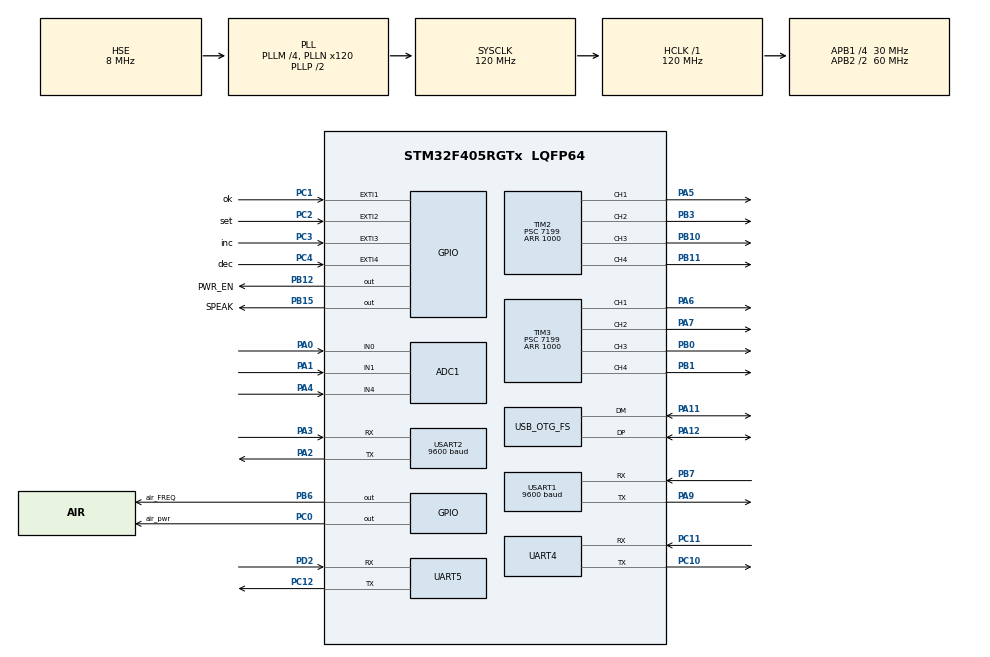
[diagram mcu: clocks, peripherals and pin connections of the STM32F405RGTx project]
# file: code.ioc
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ADC1.Channel-0\#ChannelRegularConversion=ADC_CHANNEL_0
ADC1.Channel-1\#ChannelRegularConversion=ADC_CHANNEL_1
ADC1.Channel-2\#ChannelRegularConversion=ADC_CHANNEL_4
ADC1.Channel-3\#ChannelRegularConversion=ADC_CHANNEL_VREFINT
ADC1.ContinuousConvMode=ENABLE
ADC1.DMAContinuousRequests=ENABLE
ADC1.NbrOfConversion=4
ADC1.NbrOfConversionFlag=1
ADC1.Rank-0\#ChannelRegularConversion=1
ADC1.Rank-1\#ChannelRegularConversion=2
ADC1.Rank-2\#ChannelRegularConversion=3
ADC1.Rank-3\#ChannelRegularConversion=4
ADC1.SamplingTime-0\#ChannelRegularConversion=ADC_SAMPLETIME_56CYCLES
ADC1.SamplingTime-1\#ChannelRegularConversion=ADC_SAMPLETIME_56CYCLES
ADC1.SamplingTime-2\#ChannelRegularConversion=ADC_SAMPLETIME_56CYCLES
ADC1.SamplingTime-3\#ChannelRegularConversion=ADC_SAMPLETIME_56CYCLES
ADC1.master=1
Dma.ADC1.2.Direction=DMA_PERIPH_TO_MEMORY
Dma.ADC1.2.FIFOMode=DMA_FIFOMODE_DISABLE
Dma.ADC1.2.Instance=DMA2_Stream0
Dma.ADC1.2.MemDataAlignment=DMA_MDATAALIGN_WORD
Dma.ADC1.2.MemInc=DMA_MINC_ENABLE
Dma.ADC1.2.Mode=DMA_CIRCULAR
Dma.ADC1.2.PeriphDataAlignment=DMA_PDATAALIGN_WORD
Dma.ADC1.2.PeriphInc=DMA_PINC_DISABLE
Dma.ADC1.2.Priority=DMA_PRIORITY_LOW
Dma.Request0=UART5_RX
Dma.Request1=USART2_RX
Dma.Request2=ADC1
Dma.Request3=UART4_RX
Dma.Request4=USART1_RX
Dma.UART4_RX.3.Direction=DMA_PERIPH_TO_MEMORY
Dma.UART4_RX.3.FIFOMode=DMA_FIFOMODE_DISABLE
Dma.UART4_RX.3.Instance=DMA1_Stream2
Dma.UART4_RX.3.MemDataAlignment=DMA_MDATAALIGN_BYTE
Dma.UART4_RX.3.MemInc=DMA_MINC_ENABLE
Dma.UART4_RX.3.Mode=DMA_NORMAL
Dma.UART4_RX.3.PeriphDataAlignment=DMA_PDATAALIGN_BYTE
Dma.UART4_RX.3.PeriphInc=DMA_PINC_DISABLE
Dma.UART4_RX.3.Priority=DMA_PRIORITY_LOW
Dma.UART5_RX.0.Direction=DMA_PERIPH_TO_MEMORY
Dma.UART5_RX.0.FIFOMode=DMA_FIFOMODE_DISABLE
Dma.UART5_RX.0.Instance=DMA1_Stream0
Dma.UART5_RX.0.MemDataAlignment=DMA_MDATAALIGN_BYTE
Dma.UART5_RX.0.MemInc=DMA_MINC_ENABLE
Dma.UART5_RX.0.Mode=DMA_NORMAL
Dma.UART5_RX.0.PeriphDataAlignment=DMA_PDATAALIGN_BYTE
Dma.UART5_RX.0.PeriphInc=DMA_PINC_DISABLE
Dma.UART5_RX.0.Priority=DMA_PRIORITY_LOW
Dma.USART1_RX.4.Direction=DMA_PERIPH_TO_MEMORY
Dma.USART1_RX.4.FIFOMode=DMA_FIFOMODE_DISABLE
Dma.USART1_RX.4.Instance=DMA2_Stream2
Dma.USART1_RX.4.MemDataAlignment=DMA_MDATAALIGN_BYTE
Dma.USART1_RX.4.MemInc=DMA_MINC_ENABLE
Dma.USART1_RX.4.Mode=DMA_NORMAL
Dma.USART1_RX.4.PeriphDataAlignment=DMA_PDATAALIGN_BYTE
Dma.USART1_RX.4.PeriphInc=DMA_PINC_DISABLE
Dma.USART1_RX.4.Priority=DMA_PRIORITY_LOW
Dma.USART2_RX.1.Direction=DMA_PERIPH_TO_MEMORY
Dma.USART2_RX.1.FIFOMode=DMA_FIFOMODE_DISABLE
Dma.USART2_RX.1.Instance=DMA1_Stream5
Dma.USART2_RX.1.MemDataAlignment=DMA_MDATAALIGN_BYTE
Dma.USART2_RX.1.MemInc=DMA_MINC_ENABLE
Dma.USART2_RX.1.Mode=DMA_NORMAL
Dma.USART2_RX.1.PeriphDataAlignment=DMA_PDATAALIGN_BYTE
Dma.USART2_RX.1.PeriphInc=DMA_PINC_DISABLE
Dma.USART2_RX.1.Priority=DMA_PRIORITY_LOW
FATFS._CODE_PAGE=936
FATFS._MAX_SS=4096
FATFS._USE_LFN=2
FATFS._VOLUMES=3
Mcu.Family=STM32F4
Mcu.Name=STM32F405RGTx
Mcu.Package=LQFP64
NVIC.ADC_IRQn=true\:0\:0\:false\:false\:true\:true\:true\:true
NVIC.DMA1_Stream0_IRQn=true\:0\:0\:false\:false\:true\:false\:true\:true
NVIC.DMA1_Stream2_IRQn=true\:0\:0\:false\:false\:true\:false\:true\:true
NVIC.DMA1_Stream5_IRQn=true\:0\:0\:false\:false\:true\:false\:true\:true
NVIC.DMA2_Stream0_IRQn=true\:0\:0\:false\:false\:true\:false\:true\:true
NVIC.DMA2_Stream2_IRQn=true\:0\:0\:false\:false\:true\:false\:true\:true
NVIC.EXTI1_IRQn=true\:0\:0\:false\:false\:true\:true\:true\:true
NVIC.EXTI2_IRQn=true\:0\:0\:false\:false\:true\:true\:true\:true
NVIC.EXTI3_IRQn=true\:0\:0\:false\:false\:true\:true\:true\:true
NVIC.EXTI4_IRQn=true\:0\:0\:false\:false\:true\:true\:true\:true
NVIC.OTG_FS_IRQn=true\:0\:0\:true\:false\:true\:false\:true\:true
NVIC.PVD_IRQn=true\:0\:0\:false\:false\:true\:true\:true\:true
NVIC.PriorityGroup=NVIC_PRIORITYGROUP_4
NVIC.TIM4_IRQn=true\:0\:0\:false\:false\:true\:true\:true\:true
NVIC.UART4_IRQn=true\:0\:0\:false\:false\:true\:true\:true\:true
NVIC.UART5_IRQn=true\:0\:0\:false\:false\:true\:true\:true\:true
NVIC.USART1_IRQn=true\:0\:0\:false\:false\:true\:true\:true\:true
NVIC.USART2_IRQn=true\:0\:0\:false\:false\:true\:true\:true\:true
PA0-WKUP.Signal=ADCx_IN0
PA1.Signal=ADCx_IN1
PA11.Mode=Host_Only
PA11.Signal=USB_OTG_FS_DM
PA12.Mode=Host_Only
PA12.Signal=USB_OTG_FS_DP
PA13.Mode=Serial_Wire
PA13.Signal=SYS_JTMS-SWDIO
PA14.Mode=Serial_Wire
PA14.Signal=SYS_JTCK-SWCLK
PA2.Mode=Asynchronous
PA2.Signal=USART2_TX
PA3.Mode=Asynchronous
PA3.Signal=USART2_RX
PA4.Signal=ADCx_IN4
PA5.Signal=S_TIM2_CH1_ETR
PA6.Signal=S_TIM3_CH1
PA7.Signal=S_TIM3_CH2
PA9.Mode=Asynchronous
PA9.Signal=USART1_TX
PB0.Signal=S_TIM3_CH3
PB1.Signal=S_TIM3_CH4
PB10.Signal=S_TIM2_CH3
PB11.Signal=S_TIM2_CH4
PB12.GPIO_Label=PWR_EN
PB12.Signal=GPIO_Output
PB15.GPIO_Label=SPEAK
PB15.Signal=GPIO_Output
PB3.Signal=S_TIM2_CH2
PB6.GPIO_Label=air_FREQ
PB6.Signal=GPIO_Output
PB7.Mode=Asynchronous
PB7.Signal=USART1_RX
PC0.GPIO_Label=air_pwr
PC0.Signal=GPIO_Output
PC1.GPIO_Label=ok
PC1.GPIO_ModeDefaultEXTI=GPIO_MODE_IT_FALLING
PC1.GPIO_PuPd=GPIO_PULLUP
PC1.Signal=GPXTI1
PC10.Mode=Asynchronous
PC10.Signal=UART4_TX
PC11.Mode=Asynchronous
PC11.Signal=UART4_RX
PC12.Mode=Asynchronous
PC12.Signal=UART5_TX
PC2.GPIO_Label=set
PC2.GPIO_ModeDefaultEXTI=GPIO_MODE_IT_FALLING
PC2.GPIO_PuPd=GPIO_PULLUP
PC2.Signal=GPXTI2
PC3.GPIO_Label=inc
PC3.GPIO_ModeDefaultEXTI=GPIO_MODE_IT_FALLING
PC3.GPIO_PuPd=GPIO_PULLUP
PC3.Signal=GPXTI3
PC4.GPIO_Label=dec
PC4.GPIO_ModeDefaultEXTI=GPIO_MODE_IT_FALLING
PC4.GPIO_PuPd=GPIO_PULLUP
PC4.Signal=GPXTI4
PD2.Mode=Asynchronous
PD2.Signal=UART5_RX
PH0-OSC_IN.Mode=HSE-External-Oscillator
PH0-OSC_IN.Signal=RCC_OSC_IN
PH1-OSC_OUT.Mode=HSE-External-Oscillator
PH1-OSC_OUT.Signal=RCC_OSC_OUT
ProjectManager.HeapSize=0x2000
ProjectManager.StackSize=0x2000
ProjectManager.TargetToolchain=MDK-ARM V5.32
RCC.48MHZClocksFreq_Value=48000000
RCC.AHBFreq_Value=120000000
RCC.APB1CLKDivider=RCC_HCLK_DIV4
RCC.APB1Freq_Value=30000000
RCC.APB1TimFreq_Value=60000000
RCC.APB2CLKDivider=RCC_HCLK_DIV2
RCC.APB2Freq_Value=60000000
RCC.APB2TimFreq_Value=120000000
RCC.CortexFreq_Value=120000000
RCC.HCLKFreq_Value=120000000
RCC.HSE_VALUE=8000000
RCC.HSI_VALUE=16000000
RCC.LSE_VALUE=32768
RCC.PLLM=4
RCC.PLLN=120
RCC.PLLQ=5
RCC.SYSCLKFreq_VALUE=120000000
RCC.SYSCLKSource=RCC_SYSCLKSOURCE_PLLCLK
RCC.VCOOutputFreq_Value=240000000
RTC.Format=RTC_FORMAT_BIN
RTC.Hours=14
RTC.Minutes=55
RTC.SynchPrediv=249
RTC.WakeUpClock=RTC_WAKEUPCLOCK_CK_SPRE_16BITS
RTC.WakeUpCounter=3600
RTC.Year=15
SH.ADCx_IN0.0=ADC1_IN0,IN0
SH.ADCx_IN1.0=ADC1_IN1,IN1
SH.ADCx_IN4.0=ADC1_IN4,IN4
SH.S_TIM2_CH1_ETR.0=TIM2_CH1,PWM Generation1 CH1
SH.S_TIM2_CH2.0=TIM2_CH2,PWM Generation2 CH2
SH.S_TIM2_CH3.0=TIM2_CH3,PWM Generation3 CH3
SH.S_TIM2_CH4.0=TIM2_CH4,PWM Generation4 CH4
SH.S_TIM3_CH1.0=TIM3_CH1,PWM Generation1 CH1
SH.S_TIM3_CH2.0=TIM3_CH2,PWM Generation2 CH2
SH.S_TIM3_CH3.0=TIM3_CH3,PWM Generation3 CH3
SH.S_TIM3_CH4.0=TIM3_CH4,PWM Generation4 CH4
TIM2.AutoReloadPreload=TIM_AUTORELOAD_PRELOAD_ENABLE
TIM2.Channel-PWM\ Generation1\ CH1=TIM_CHANNEL_1
TIM2.Channel-PWM\ Generation2\ CH2=TIM_CHANNEL_2
TIM2.Channel-PWM\ Generation3\ CH3=TIM_CHANNEL_3
TIM2.Channel-PWM\ Generation4\ CH4=TIM_CHANNEL_4
TIM2.Period=1000
TIM2.Prescaler=7199
TIM3.Channel-PWM\ Generation1\ CH1=TIM_CHANNEL_1
TIM3.Channel-PWM\ Generation2\ CH2=TIM_CHANNEL_2
TIM3.Channel-PWM\ Generation3\ CH3=TIM_CHANNEL_3
TIM3.Channel-PWM\ Generation4\ CH4=TIM_CHANNEL_4
TIM3.Period=1000
TIM3.Prescaler=7199
TIM3.Pulse-PWM\ Generation1\ CH1=5
TIM4.AutoReloadPreload=TIM_AUTORELOAD_PRELOAD_ENABLE
TIM4.Period=999
TIM4.Prescaler=71
UART4.VirtualMode=Asynchronous
UART5.VirtualMode=Asynchronous
USART1.BaudRate=9600
USART1.VirtualMode=VM_ASYNC
USART2.BaudRate=9600
USART2.VirtualMode=VM_ASYNC
USB_HOST.USBH_DEBUG_LEVEL-MSC_FS=2
USB_HOST.USBH_HandleTypeDef-MSC_FS=hUsbHostFS
USB_HOST.VirtualModeFS=Msc
USB_OTG_FS.VirtualMode=Host_Only
USB_OTG_FS.phy_itface=HCD_PHY_EMBEDDED
VP_ADC1_Vref_Input.Mode=IN-Vrefint
VP_FATFS_VS_USB.Mode=USB
VP_RTC_VS_RTC_Activate.Mode=RTC_Enabled
VP_RTC_VS_RTC_WakeUp_intern.Mode=WakeUp
VP_TIM4_VS_ClockSourceINT.Mode=Internal
VP_USB_HOST_VS_USB_HOST_MSC_FS.Mode=MSC_FS
board=custom

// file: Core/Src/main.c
/* USER CODE BEGIN Header */
/**
  ******************************************************************************
  * @file           : main.c
  * @brief          : Main program body
  ******************************************************************************
  * @attention
  *
  * Copyright (c) 2024 STMicroelectronics.
  * All rights reserved.
  *
  * This software is licensed under terms that can be found in the LICENSE file
  * in the root directory of this software component.
  * If no LICENSE file comes with this software, it is provided AS-IS.
  *
  ******************************************************************************
  */
/* USER CODE END Header */
#include "main.h"
#include "fatfs.h"
#include "usb_host.h"

/* USER CODE BEGIN Includes */
#include "air.h"

/* USER CODE END Includes */

ADC_HandleTypeDef hadc1;
DMA_HandleTypeDef hdma_adc1;

RTC_HandleTypeDef hrtc;

TIM_HandleTypeDef htim2;
TIM_HandleTypeDef htim3;
TIM_HandleTypeDef htim4;

UART_HandleTypeDef huart4;
UART_HandleTypeDef huart5;
UART_HandleTypeDef huart1;
UART_HandleTypeDef huart2;
DMA_HandleTypeDef hdma_uart4_rx;
DMA_HandleTypeDef hdma_uart5_rx;
DMA_HandleTypeDef hdma_usart1_rx;
DMA_HandleTypeDef hdma_usart2_rx;

/* USER CODE BEGIN PV */
USBH_HandleTypeDef hUSBHost;    /* USB Host处理结构体 */
/* USER CODE END PV */

void SystemClock_Config(void);
static void MX_GPIO_Init(void);
static void MX_DMA_Init(void);
static void MX_ADC1_Init(void);
static void MX_TIM2_Init(void);
static void MX_TIM3_Init(void);
static void MX_UART4_Init(void);
static void MX_USART1_UART_Init(void);
static void MX_USART2_UART_Init(void);
static void MX_UART5_Init(void);
static void MX_TIM4_Init(void);
static void MX_RTC_Init(void);
void MX_USB_HOST_Process(void);

/* USER CODE BEGIN PFP */
FATFS *fs[FF_VOLUMES];
/* USER CODE END PFP */

/* USER CODE BEGIN 0 */
//static void USBH_UserProcess(USBH_HandleTypeDef *phost, uint8_t id)
//{
//    uint32_t total, free;
//    uint8_t res = 0;
//    printf("id:%d\r\n", id);

//    switch (id)
//    {
//        case HOST_USER_SELECT_CONFIGURATION:
//            break;

//        case HOST_USER_DISCONNECTION:
//            f_mount(0, "2:", 1);        /* 卸载U盘 */
//           // text_show_string(30, 120, 200, 16, "设备连接中...", 16, 0, RED);
//            //lcd_fill(30, 160, 239, 220, WHITE);
//            break;

//        case HOST_USER_CLASS_ACTIVE:
//            //text_show_string(30, 120, 200, 16, "设备连接成功!", 16, 0, RED);
//            f_mount(fs[2], "2:", 1);    /* 重新挂载U盘 */
//            res = exfuns_get_free("2:", &total, &free);

//            if (res == 0)
//            {
////                lcd_show_string(30, 160, 200, 16, 16, "FATFS OK!", BLUE);
////                lcd_show_string(30, 180, 200, 16, 16, "U Disk Total Size:     MB", BLUE);
////                lcd_show_string(30, 200, 200, 16, 16, "U Disk  Free Size:     MB", BLUE);
////                lcd_show_num(174, 180, total >> 10, 5, 16, BLUE);   /* 显示U盘总容量 MB */
////                lcd_show_num(174, 200, free >> 10, 5, 16, BLUE);
//            }
//            else
//            {
//                printf("U盘存储空间获取失败\r\n");
//            }

//            break;

//        case HOST_USER_CONNECTION:
//            break;

//        default:
//            break;
//    }
//}
/* USER CODE END 0 */

int main(void)
{

  /* MCU Configuration--------------------------------------------------------*/

  /* Reset of all peripherals, Initializes the Flash interface and the Systick. */
  HAL_Init();

  /* Configure the system clock */
  SystemClock_Config();

  /* Initialize all configured peripherals */
  MX_GPIO_Init();
  MX_DMA_Init();
  MX_ADC1_Init();
  MX_TIM2_Init();
  MX_TIM3_Init();
  MX_UART4_Init();
  MX_USART1_UART_Init();
  MX_USART2_UART_Init();
  MX_UART5_Init();
  MX_TIM4_Init();
  MX_FATFS_Init();
  MX_USB_HOST_Init();
  MX_RTC_Init();
  /* USER CODE BEGIN 2 */
  //  USBH_Init(&hUSBHost, USBH_UserProcess, 0);
    USBH_RegisterClass(&hUSBHost, USBH_MSC_CLASS);
    USBH_Start(&hUSBHost);
	app_init();
  /* USER CODE END 2 */

  /* Infinite loop */
  while (1)
  {
    MX_USB_HOST_Process();

    /* USER CODE BEGIN 3 */
		app();
		HAL_GPIO_WritePin(PWR_EN_GPIO_Port, PWR_EN_Pin, GPIO_PIN_SET);
  }
  /* USER CODE END 3 */
}

void SystemClock_Config(void)
{
  RCC_OscInitTypeDef RCC_OscInitStruct = {0};
  RCC_ClkInitTypeDef RCC_ClkInitStruct = {0};

  /** Configure the main internal regulator output voltage
  */
  __HAL_RCC_PWR_CLK_ENABLE();
  __HAL_PWR_VOLTAGESCALING_CONFIG(PWR_REGULATOR_VOLTAGE_SCALE1);

  /** Initializes the RCC Oscillators according to the specified parameters
  * in the RCC_OscInitTypeDef structure.
  */
  RCC_OscInitStruct.OscillatorType = RCC_OSCILLATORTYPE_LSI|RCC_OSCILLATORTYPE_HSE;
  RCC_OscInitStruct.HSEState = RCC_HSE_ON;
  RCC_OscInitStruct.LSIState = RCC_LSI_ON;
  RCC_OscInitStruct.PLL.PLLState = RCC_PLL_ON;
  RCC_OscInitStruct.PLL.PLLSource = RCC_PLLSOURCE_HSE;
  RCC_OscInitStruct.PLL.PLLM = 4;
  RCC_OscInitStruct.PLL.PLLN = 120;
  RCC_OscInitStruct.PLL.PLLP = RCC_PLLP_DIV2;
  RCC_OscInitStruct.PLL.PLLQ = 5;
  if (HAL_RCC_OscConfig(&RCC_OscInitStruct) != HAL_OK)
  {
    Error_Handler();
  }

  /** Initializes the CPU, AHB and APB buses clocks
  */
  RCC_ClkInitStruct.ClockType = RCC_CLOCKTYPE_HCLK|RCC_CLOCKTYPE_SYSCLK
                              |RCC_CLOCKTYPE_PCLK1|RCC_CLOCKTYPE_PCLK2;
  RCC_ClkInitStruct.SYSCLKSource = RCC_SYSCLKSOURCE_PLLCLK;
  RCC_ClkInitStruct.AHBCLKDivider = RCC_SYSCLK_DIV1;
  RCC_ClkInitStruct.APB1CLKDivider = RCC_HCLK_DIV4;
  RCC_ClkInitStruct.APB2CLKDivider = RCC_HCLK_DIV2;

  if (HAL_RCC_ClockConfig(&RCC_ClkInitStruct, FLASH_LATENCY_3) != HAL_OK)
  {
    Error_Handler();
  }
}

static void MX_ADC1_Init(void)
{

  ADC_ChannelConfTypeDef sConfig = {0};

  /** Configure the global features of the ADC (Clock, Resolution, Data Alignment and number of conversion)
  */
  hadc1.Instance = ADC1;
  hadc1.Init.ClockPrescaler = ADC_CLOCK_SYNC_PCLK_DIV2;
  hadc1.Init.Resolution = ADC_RESOLUTION_12B;
  hadc1.Init.ScanConvMode = ENABLE;
  hadc1.Init.ContinuousConvMode = ENABLE;
  hadc1.Init.DiscontinuousConvMode = DISABLE;
  hadc1.Init.ExternalTrigConvEdge = ADC_EXTERNALTRIGCONVEDGE_NONE;
  hadc1.Init.ExternalTrigConv = ADC_SOFTWARE_START;
  hadc1.Init.DataAlign = ADC_DATAALIGN_RIGHT;
  hadc1.Init.NbrOfConversion = 4;
  hadc1.Init.DMAContinuousRequests = ENABLE;
  hadc1.Init.EOCSelection = ADC_EOC_SINGLE_CONV;
  if (HAL_ADC_Init(&hadc1) != HAL_OK)
  {
    Error_Handler();
  }

  /** Configure for the selected ADC regular channel its corresponding rank in the sequencer and its sample time.
  */
  sConfig.Channel = ADC_CHANNEL_0;
  sConfig.Rank = 1;
  sConfig.SamplingTime = ADC_SAMPLETIME_56CYCLES;
  if (HAL_ADC_ConfigChannel(&hadc1, &sConfig) != HAL_OK)
  {
    Error_Handler();
  }

  /** Configure for the selected ADC regular channel its corresponding rank in the sequencer and its sample time.
  */
  sConfig.Channel = ADC_CHANNEL_1;
  sConfig.Rank = 2;
  if (HAL_ADC_ConfigChannel(&hadc1, &sConfig) != HAL_OK)
  {
    Error_Handler();
  }

  /** Configure for the selected ADC regular channel its corresponding rank in the sequencer and its sample time.
  */
  sConfig.Channel = ADC_CHANNEL_4;
  sConfig.Rank = 3;
  if (HAL_ADC_ConfigChannel(&hadc1, &sConfig) != HAL_OK)
  {
    Error_Handler();
  }

  /** Configure for the selected ADC regular channel its corresponding rank in the sequencer and its sample time.
  */
  sConfig.Channel = ADC_CHANNEL_VREFINT;
  sConfig.Rank = 4;
  if (HAL_ADC_ConfigChannel(&hadc1, &sConfig) != HAL_OK)
  {
    Error_Handler();
  }

}

static void MX_RTC_Init(void)
{

  RTC_TimeTypeDef sTime = {0};
  RTC_DateTypeDef sDate = {0};

  /** Initialize RTC Only
  */
  hrtc.Instance = RTC;
  hrtc.Init.HourFormat = RTC_HOURFORMAT_24;
  hrtc.Init.AsynchPrediv = 127;
  hrtc.Init.SynchPrediv = 249;
  hrtc.Init.OutPut = RTC_OUTPUT_DISABLE;
  hrtc.Init.OutPutPolarity = RTC_OUTPUT_POLARITY_HIGH;
  hrtc.Init.OutPutType = RTC_OUTPUT_TYPE_OPENDRAIN;
  if (HAL_RTC_Init(&hrtc) != HAL_OK)
  {
    Error_Handler();
  }

  /** Initialize RTC and set the Time and Date
  */
  sTime.Hours = 14;
  sTime.Minutes = 55;
  sTime.Seconds = 0;
  sTime.DayLightSaving = RTC_DAYLIGHTSAVING_NONE;
  sTime.StoreOperation = RTC_STOREOPERATION_RESET;
  if (HAL_RTC_SetTime(&hrtc, &sTime, RTC_FORMAT_BIN) != HAL_OK)
  {
    Error_Handler();
  }
  sDate.WeekDay = RTC_WEEKDAY_MONDAY;
  sDate.Month = RTC_MONTH_JANUARY;
  sDate.Date = 1;
  sDate.Year = 15;

  if (HAL_RTC_SetDate(&hrtc, &sDate, RTC_FORMAT_BIN) != HAL_OK)
  {
    Error_Handler();
  }

  /** Enable the WakeUp
  */
  if (HAL_RTCEx_SetWakeUpTimer(&hrtc, 3600, RTC_WAKEUPCLOCK_CK_SPRE_16BITS) != HAL_OK)
  {
    Error_Handler();
  }

}

static void MX_TIM2_Init(void)
{

  TIM_MasterConfigTypeDef sMasterConfig = {0};
  TIM_OC_InitTypeDef sConfigOC = {0};

  htim2.Instance = TIM2;
  htim2.Init.Prescaler = 7199;
  htim2.Init.CounterMode = TIM_COUNTERMODE_UP;
  htim2.Init.Period = 1000;
  htim2.Init.ClockDivision = TIM_CLOCKDIVISION_DIV1;
  htim2.Init.AutoReloadPreload = TIM_AUTORELOAD_PRELOAD_ENABLE;
  if (HAL_TIM_PWM_Init(&htim2) != HAL_OK)
  {
    Error_Handler();
  }
  sMasterConfig.MasterOutputTrigger = TIM_TRGO_RESET;
  sMasterConfig.MasterSlaveMode = TIM_MASTERSLAVEMODE_DISABLE;
  if (HAL_TIMEx_MasterConfigSynchronization(&htim2, &sMasterConfig) != HAL_OK)
  {
    Error_Handler();
  }
  sConfigOC.OCMode = TIM_OCMODE_PWM1;
  sConfigOC.Pulse = 0;
  sConfigOC.OCPolarity = TIM_OCPOLARITY_HIGH;
  sConfigOC.OCFastMode = TIM_OCFAST_DISABLE;
  if (HAL_TIM_PWM_ConfigChannel(&htim2, &sConfigOC, TIM_CHANNEL_1) != HAL_OK)
  {
    Error_Handler();
  }
  if (HAL_TIM_PWM_ConfigChannel(&htim2, &sConfigOC, TIM_CHANNEL_2) != HAL_OK)
  {
    Error_Handler();
  }
  if (HAL_TIM_PWM_ConfigChannel(&htim2, &sConfigOC, TIM_CHANNEL_3) != HAL_OK)
  {
    Error_Handler();
  }
  if (HAL_TIM_PWM_ConfigChannel(&htim2, &sConfigOC, TIM_CHANNEL_4) != HAL_OK)
  {
    Error_Handler();
  }
  HAL_TIM_MspPostInit(&htim2);

}

static void MX_TIM3_Init(void)
{

  TIM_MasterConfigTypeDef sMasterConfig = {0};
  TIM_OC_InitTypeDef sConfigOC = {0};

  htim3.Instance = TIM3;
  htim3.Init.Prescaler = 7199;
  htim3.Init.CounterMode = TIM_COUNTERMODE_UP;
  htim3.Init.Period = 1000;
  htim3.Init.ClockDivision = TIM_CLOCKDIVISION_DIV1;
  htim3.Init.AutoReloadPreload = TIM_AUTORELOAD_PRELOAD_DISABLE;
  if (HAL_TIM_PWM_Init(&htim3) != HAL_OK)
  {
    Error_Handler();
  }
  sMasterConfig.MasterOutputTrigger = TIM_TRGO_RESET;
  sMasterConfig.MasterSlaveMode = TIM_MASTERSLAVEMODE_DISABLE;
  if (HAL_TIMEx_MasterConfigSynchronization(&htim3, &sMasterConfig) != HAL_OK)
  {
    Error_Handler();
  }
  sConfigOC.OCMode = TIM_OCMODE_PWM1;
  sConfigOC.Pulse = 5;
  sConfigOC.OCPolarity = TIM_OCPOLARITY_HIGH;
  sConfigOC.OCFastMode = TIM_OCFAST_DISABLE;
  if (HAL_TIM_PWM_ConfigChannel(&htim3, &sConfigOC, TIM_CHANNEL_1) != HAL_OK)
  {
    Error_Handler();
  }
  sConfigOC.Pulse = 0;
  if (HAL_TIM_PWM_ConfigChannel(&htim3, &sConfigOC, TIM_CHANNEL_2) != HAL_OK)
  {
    Error_Handler();
  }
  if (HAL_TIM_PWM_ConfigChannel(&htim3, &sConfigOC, TIM_CHANNEL_3) != HAL_OK)
  {
    Error_Handler();
  }
  if (HAL_TIM_PWM_ConfigChannel(&htim3, &sConfigOC, TIM_CHANNEL_4) != HAL_OK)
  {
    Error_Handler();
  }
  HAL_TIM_MspPostInit(&htim3);

}

static void MX_TIM4_Init(void)
{

  TIM_ClockConfigTypeDef sClockSourceConfig = {0};
  TIM_MasterConfigTypeDef sMasterConfig = {0};

  htim4.Instance = TIM4;
  htim4.Init.Prescaler = 71;
  htim4.Init.CounterMode = TIM_COUNTERMODE_UP;
  htim4.Init.Period = 999;
  htim4.Init.ClockDivision = TIM_CLOCKDIVISION_DIV1;
  htim4.Init.AutoReloadPreload = TIM_AUTORELOAD_PRELOAD_ENABLE;
  if (HAL_TIM_Base_Init(&htim4) != HAL_OK)
  {
    Error_Handler();
  }
  sClockSourceConfig.ClockSource = TIM_CLOCKSOURCE_INTERNAL;
  if (HAL_TIM_ConfigClockSource(&htim4, &sClockSourceConfig) != HAL_OK)
  {
    Error_Handler();
  }
  sMasterConfig.MasterOutputTrigger = TIM_TRGO_RESET;
  sMasterConfig.MasterSlaveMode = TIM_MASTERSLAVEMODE_DISABLE;
  if (HAL_TIMEx_MasterConfigSynchronization(&htim4, &sMasterConfig) != HAL_OK)
  {
    Error_Handler();
  }

}

static void MX_UART4_Init(void)
{

  huart4.Instance = UART4;
  huart4.Init.BaudRate = 115200;
  huart4.Init.WordLength = UART_WORDLENGTH_8B;
  huart4.Init.StopBits = UART_STOPBITS_1;
  huart4.Init.Parity = UART_PARITY_NONE;
  huart4.Init.Mode = UART_MODE_TX_RX;
  huart4.Init.HwFlowCtl = UART_HWCONTROL_NONE;
  huart4.Init.OverSampling = UART_OVERSAMPLING_16;
  if (HAL_UART_Init(&huart4) != HAL_OK)
  {
    Error_Handler();
  }

}

static void MX_UART5_Init(void)
{

  huart5.Instance = UART5;
  huart5.Init.BaudRate = 115200;
  huart5.Init.WordLength = UART_WORDLENGTH_8B;
  huart5.Init.StopBits = UART_STOPBITS_1;
  huart5.Init.Parity = UART_PARITY_NONE;
  huart5.Init.Mode = UART_MODE_TX_RX;
  huart5.Init.HwFlowCtl = UART_HWCONTROL_NONE;
  huart5.Init.OverSampling = UART_OVERSAMPLING_16;
  if (HAL_UART_Init(&huart5) != HAL_OK)
  {
    Error_Handler();
  }

}

static void MX_USART1_UART_Init(void)
{

  huart1.Instance = USART1;
  huart1.Init.BaudRate = 9600;
  huart1.Init.WordLength = UART_WORDLENGTH_8B;
  huart1.Init.StopBits = UART_STOPBITS_1;
  huart1.Init.Parity = UART_PARITY_NONE;
  huart1.Init.Mode = UART_MODE_TX_RX;
  huart1.Init.HwFlowCtl = UART_HWCONTROL_NONE;
  huart1.Init.OverSampling = UART_OVERSAMPLING_16;
  if (HAL_UART_Init(&huart1) != HAL_OK)
  {
    Error_Handler();
  }

}

static void MX_USART2_UART_Init(void)
{

  huart2.Instance = USART2;
  huart2.Init.BaudRate = 9600;
  huart2.Init.WordLength = UART_WORDLENGTH_8B;
  huart2.Init.StopBits = UART_STOPBITS_1;
  huart2.Init.Parity = UART_PARITY_NONE;
  huart2.Init.Mode = UART_MODE_TX_RX;
  huart2.Init.HwFlowCtl = UART_HWCONTROL_NONE;
  huart2.Init.OverSampling = UART_OVERSAMPLING_16;
  if (HAL_UART_Init(&huart2) != HAL_OK)
  {
    Error_Handler();
  }

}

static void MX_DMA_Init(void)
{

  /* DMA controller clock enable */
  __HAL_RCC_DMA1_CLK_ENABLE();
  __HAL_RCC_DMA2_CLK_ENABLE();

  /* DMA interrupt init */
  /* DMA1_Stream0_IRQn interrupt configuration */
  HAL_NVIC_SetPriority(DMA1_Stream0_IRQn, 0, 0);
  HAL_NVIC_EnableIRQ(DMA1_Stream0_IRQn);
  /* DMA1_Stream2_IRQn interrupt configuration */
  HAL_NVIC_SetPriority(DMA1_Stream2_IRQn, 0, 0);
  HAL_NVIC_EnableIRQ(DMA1_Stream2_IRQn);
  /* DMA1_Stream5_IRQn interrupt configuration */
  HAL_NVIC_SetPriority(DMA1_Stream5_IRQn, 0, 0);
  HAL_NVIC_EnableIRQ(DMA1_Stream5_IRQn);
  /* DMA2_Stream0_IRQn interrupt configuration */
  HAL_NVIC_SetPriority(DMA2_Stream0_IRQn, 0, 0);
  HAL_NVIC_EnableIRQ(DMA2_Stream0_IRQn);
  /* DMA2_Stream2_IRQn interrupt configuration */
  HAL_NVIC_SetPriority(DMA2_Stream2_IRQn, 0, 0);
  HAL_NVIC_EnableIRQ(DMA2_Stream2_IRQn);

}

static void MX_GPIO_Init(void)
{
  GPIO_InitTypeDef GPIO_InitStruct = {0};

  /* GPIO Ports Clock Enable */
  __HAL_RCC_GPIOH_CLK_ENABLE();
  __HAL_RCC_GPIOC_CLK_ENABLE();
  __HAL_RCC_GPIOA_CLK_ENABLE();
  __HAL_RCC_GPIOB_CLK_ENABLE();
  __HAL_RCC_GPIOD_CLK_ENABLE();

  /*Configure GPIO pin Output Level */
  HAL_GPIO_WritePin(air_pwr_GPIO_Port, air_pwr_Pin, GPIO_PIN_RESET);

  /*Configure GPIO pin Output Level */
  HAL_GPIO_WritePin(GPIOB, PWR_EN_Pin|SPEAK_Pin|air_FREQ_Pin, GPIO_PIN_RESET);

  /*Configure GPIO pin : air_pwr_Pin */
  GPIO_InitStruct.Pin = air_pwr_Pin;
  GPIO_InitStruct.Mode = GPIO_MODE_OUTPUT_PP;
  GPIO_InitStruct.Pull = GPIO_NOPULL;
  GPIO_InitStruct.Speed = GPIO_SPEED_FREQ_LOW;
  HAL_GPIO_Init(air_pwr_GPIO_Port, &GPIO_InitStruct);

  /*Configure GPIO pins : ok_Pin set_Pin inc_Pin dec_Pin */
  GPIO_InitStruct.Pin = ok_Pin|set_Pin|inc_Pin|dec_Pin;
  GPIO_InitStruct.Mode = GPIO_MODE_IT_FALLING;
  GPIO_InitStruct.Pull = GPIO_PULLUP;
  HAL_GPIO_Init(GPIOC, &GPIO_InitStruct);

  /*Configure GPIO pins : PWR_EN_Pin SPEAK_Pin air_FREQ_Pin */
  GPIO_InitStruct.Pin = PWR_EN_Pin|SPEAK_Pin|air_FREQ_Pin;
  GPIO_InitStruct.Mode = GPIO_MODE_OUTPUT_PP;
  GPIO_InitStruct.Pull = GPIO_NOPULL;
  GPIO_InitStruct.Speed = GPIO_SPEED_FREQ_LOW;
  HAL_GPIO_Init(GPIOB, &GPIO_InitStruct);

  /* EXTI interrupt init*/
  HAL_NVIC_SetPriority(EXTI1_IRQn, 0, 0);
  HAL_NVIC_EnableIRQ(EXTI1_IRQn);

  HAL_NVIC_SetPriority(EXTI2_IRQn, 0, 0);
  HAL_NVIC_EnableIRQ(EXTI2_IRQn);

  HAL_NVIC_SetPriority(EXTI3_IRQn, 0, 0);
  HAL_NVIC_EnableIRQ(EXTI3_IRQn);

  HAL_NVIC_SetPriority(EXTI4_IRQn, 0, 0);
  HAL_NVIC_EnableIRQ(EXTI4_IRQn);

}

void Error_Handler(void)
{
  __disable_irq();
  while (1)
  {
  }
}
